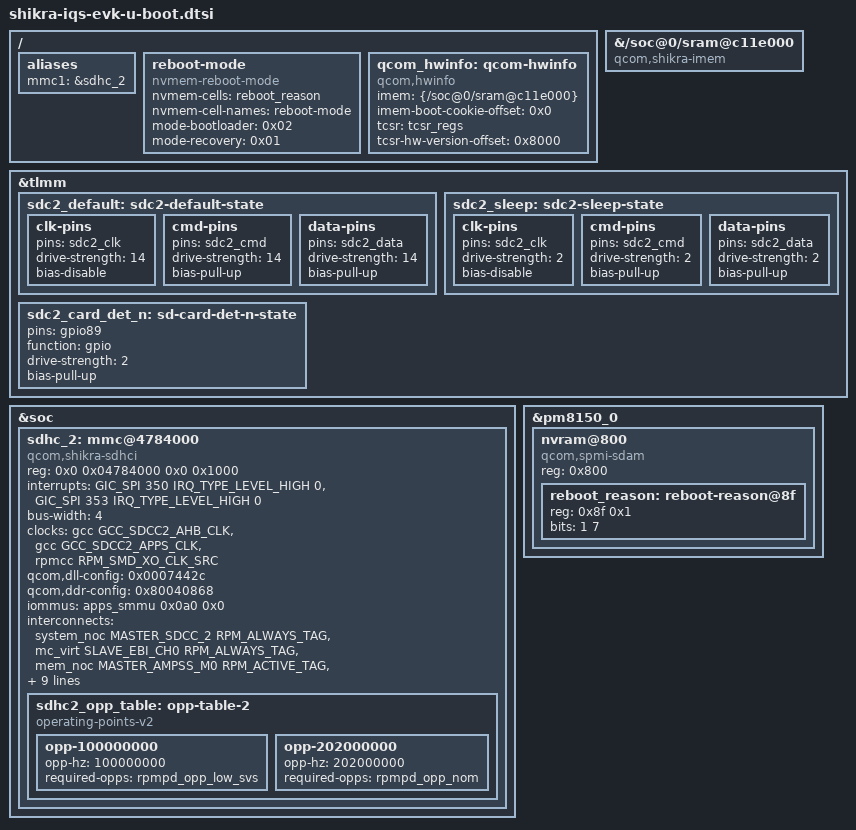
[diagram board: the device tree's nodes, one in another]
// SPDX-License-Identifier: BSD-3-Clause
/*
 * Copyright (c) Qualcomm Technologies, Inc. and/or its subsidiaries.
 */

#include "shikra-usb-u-boot.dtsi"

/ {
	aliases {
		mmc1 = &sdhc_2;
	};

	reboot-mode {
		compatible = "nvmem-reboot-mode";
		nvmem-cells = <&reboot_reason>;
		nvmem-cell-names = "reboot-mode";

		mode-bootloader = <0x02>;
		mode-recovery   = <0x01>;
	};

	qcom_hwinfo: qcom-hwinfo {
		compatible = "qcom,hwinfo";

		imem = <&{/soc@0/sram@c11e000}>;
		imem-boot-cookie-offset = <0x0>;

		tcsr = <&tcsr_regs>;
		tcsr-hw-version-offset = <0x8000>;
	};
};

&{/soc@0/sram@c11e000} {
	compatible = "qcom,shikra-imem", "syscon", "simple-mfd";
};

&tlmm {
	sdc2_default: sdc2-default-state {
		clk-pins {
			pins = "sdc2_clk";
			drive-strength = <14>;
			bias-disable;
		};

		cmd-pins {
			pins = "sdc2_cmd";
			drive-strength = <14>;
			bias-pull-up;
		};

		data-pins {
			pins = "sdc2_data";
			drive-strength = <14>;
			bias-pull-up;
		};
	};

	sdc2_sleep: sdc2-sleep-state {
		clk-pins {
			pins = "sdc2_clk";
			drive-strength = <2>;
			bias-disable;
		};

		cmd-pins {
			pins = "sdc2_cmd";
			drive-strength = <2>;
			bias-pull-up;
		};

		data-pins {
			pins = "sdc2_data";
			drive-strength = <2>;
			bias-pull-up;
		};
	};

	sdc2_card_det_n: sd-card-det-n-state {
		pins = "gpio89";
		function = "gpio";
		drive-strength = <2>;
		bias-pull-up;
	};
};

&soc {
	sdhc_2: mmc@4784000 {
		compatible = "qcom,shikra-sdhci", "qcom,sdhci-msm-v5";
		reg = <0x0 0x04784000 0x0 0x1000>;

		interrupts = <GIC_SPI 350 IRQ_TYPE_LEVEL_HIGH 0>,
			     <GIC_SPI 353 IRQ_TYPE_LEVEL_HIGH 0>;
		interrupt-names = "hc_irq", "pwr_irq";

		bus-width = <4>;

		clocks = <&gcc GCC_SDCC2_AHB_CLK>,
			 <&gcc GCC_SDCC2_APPS_CLK>,
			 <&rpmcc RPM_SMD_XO_CLK_SRC>;
		clock-names = "iface", "core", "xo";

		qcom,dll-config = <0x0007442c>;
		qcom,ddr-config = <0x80040868>;

		iommus = <&apps_smmu 0x0a0 0x0>;

		interconnects = <&system_noc MASTER_SDCC_2 RPM_ALWAYS_TAG
				 &mc_virt SLAVE_EBI_CH0 RPM_ALWAYS_TAG>,
				<&mem_noc MASTER_AMPSS_M0 RPM_ACTIVE_TAG
				 &config_noc SLAVE_SDCC_2 RPM_ACTIVE_TAG>;
		interconnect-names = "sdhc-ddr", "cpu-sdhc";
		operating-points-v2 = <&sdhc2_opp_table>;

		sdhc2_opp_table: opp-table-2 {
			compatible = "operating-points-v2";

			opp-100000000 {
				opp-hz = /bits/ 64 <100000000>;
				required-opps = <&rpmpd_opp_low_svs>;
			};

			opp-202000000 {
				opp-hz = /bits/ 64 <202000000>;
				required-opps = <&rpmpd_opp_nom>;
			};
		};
	};
};

&sdhc_2 {
	vmmc-supply = <&pm8150_l10>;
	vqmmc-supply = <&pm8150_l2>;

	no-sdio;
	no-mmc;

	pinctrl-0 = <&sdc2_default &sdc2_card_det_n>;
	pinctrl-1 = <&sdc2_sleep &sdc2_card_det_n>;
	pinctrl-names = "default", "sleep";

	cd-gpios = <&tlmm 89 GPIO_ACTIVE_LOW>;

	status = "okay";
};

&pm8150_0 {
	/* Virtual NVMEM node for PON-based reboot reason storage */
	nvram@800 {
		compatible = "qcom,spmi-sdam";
		reg = <0x800>;
		#address-cells = <1>;
		#size-cells = <1>;
		ranges = <0x00 0x800 0x100>;

		/* Reboot reason cell at PON_SOFT_RB_SPARE (0x88F) */
		reboot_reason: reboot-reason@8f {
			reg = <0x8f 0x1>;
			bits = <1 7>;
		};
	};
};
